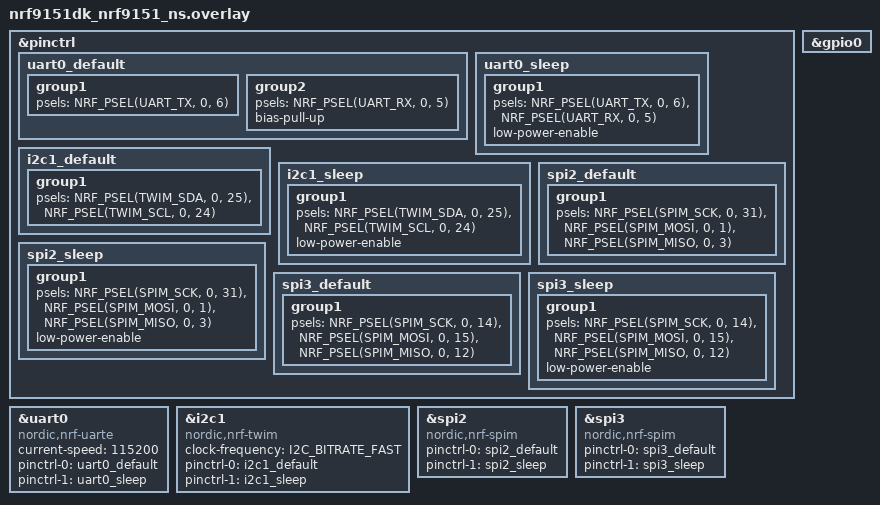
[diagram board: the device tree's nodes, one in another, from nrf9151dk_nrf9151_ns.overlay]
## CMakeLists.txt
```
#
# Copyright (c) 2023 Nordic Semiconductor
#
# SPDX-License-Identifier: LicenseRef-Nordic-5-Clause
#

cmake_minimum_required(VERSION 3.20.0)

find_package(Zephyr REQUIRED HINTS $ENV{ZEPHYR_BASE})
project(N2)
zephyr_compile_definitions(PROJECT_NAME=${PROJECT_NAME})

# NORDIC SDK APP START
target_sources(app PRIVATE src/main.c)
# NORDIC SDK APP END

# Include source directory
target_include_directories(app PRIVATE src)
target_include_directories(app PRIVATE $ENV{ZEPHYR_BASE}/subsys/fs/nvs)

# Application directories
add_subdirectory(src/menu)
add_subdirectory(src/datetime)
add_subdirectory(src/strings)
add_subdirectory(src/font)
add_subdirectory(src/image)
add_subdirectory(src/lcd)
add_subdirectory(src/key)
add_subdirectory(src/settings)
add_subdirectory(src/inner_flash)
add_subdirectory(src/external_flash)
add_subdirectory(src/uart)
add_subdirectory(src/gps)
add_subdirectory(src/nb)
add_subdirectory(src/screen)
add_subdirectory(src/pmu)
add_subdirectory(src/sos)
add_subdirectory(src/codetrans)
add_subdirectory(src/ucs2)
add_subdirectory(src/communicate)
add_subdirectory(src/logger)

add_subdirectory_ifdef(CONFIG_ALARM_SUPPORT src/alarm)
add_subdirectory_ifdef(CONFIG_ANIMATION_SUPPORT src/animation)
add_subdirectory_ifdef(CONFIG_TOUCH_SUPPORT src/tp)
add_subdirectory_ifdef(CONFIG_IMU_SUPPORT src/imu)
add_subdirectory_ifdef(CONFIG_PPG_SUPPORT src/ppg)
add_subdirectory_ifdef(CONFIG_ECG_SUPPORT src/ecg)
add_subdirectory_ifdef(CONFIG_BLE_SUPPORT src/ble)
add_subdirectory_ifdef(CONFIG_AUDIO_SUPPORT src/audio)
add_subdirectory_ifdef(CONFIG_TEMP_SUPPORT src/temperature)
add_subdirectory_ifdef(CONFIG_CRC_SUPPORT src/crc_check)
add_subdirectory_ifdef(CONFIG_SYNC_SUPPORT src/sync)
add_subdirectory_ifdef(CONFIG_WIFI_SUPPORT src/wifi)
add_subdirectory_ifdef(CONFIG_WATCHDOG src/watchdog)
add_subdirectory_ifdef(CONFIG_FOTA_DOWNLOAD src/fota)
add_subdirectory_ifdef(CONFIG_DATA_DOWNLOAD_SUPPORT src/data_download)
add_subdirectory_ifdef(CONFIG_BARCODE_SUPPORT src/barcode)
add_subdirectory_ifdef(CONFIG_QRCODE_SUPPORT src/qrcode)
add_subdirectory_ifdef(CONFIG_FACTORY_TEST_SUPPORT src/factory_test)
add_subdirectory_ifdef(CONFIG_PRESSURE_SUPPORT src/pressure)
```

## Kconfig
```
#
# Copyright (c) 2021 Nordic Semiconductor ASA
#
# SPDX-License-Identifier: LicenseRef-Nordic-5-Clause
#
choice LOG_MODE
	default LOG_MODE_IMMEDIATE
endchoice

menu "GPS"
config GPS_SUPPORT
	bool "gps support"
	default n
endmenu #GPS

menu "GNSS"
choice
	default GNSS_SAMPLE_MODE_CONTINUOUS
	prompt "Select GNSS operation mode"

config GNSS_SAMPLE_MODE_CONTINUOUS
	bool "Continuous tracking"

config GNSS_SAMPLE_MODE_PERIODIC
	bool "Periodic fixes"

config GNSS_SAMPLE_MODE_TTFF_TEST
	bool "Time-to-first-fix (TTFF) test mode"
	select GNSS_SAMPLE_NMEA_ONLY
endchoice

if GNSS_SAMPLE_MODE_PERIODIC
config GNSS_SAMPLE_PERIODIC_INTERVAL
	int "Fix interval for periodic fixes"
	range 10 65535
	default 120
	help
	  Fix interval (in seconds) for periodic fixes.
config GNSS_SAMPLE_PERIODIC_TIMEOUT
	int "Fix timeout for periodic fixes"
	range 0 65535
	default 120
	help
	  Fix timeout (in seconds) for periodic fixes.
	  If set to zero, GNSS is allowed to run indefinitely until a valid PVT estimate is produced.
endif # GNSS_SAMPLE_MODE_PERIODIC

if GNSS_SAMPLE_MODE_TTFF_TEST
config GNSS_SAMPLE_MODE_TTFF_TEST_COLD_START
	bool "Delete GNSS data before each start (cold start)"
	help
	  When enabled, deletes all stored data from GNSS to force a cold start every time GNSS is started.
config GNSS_SAMPLE_MODE_TTFF_TEST_INTERVAL
	int "Time to wait between TTFF tests in seconds"
	range 1 604800
	default 120
endif # GNSS_SAMPLE_MODE_TTFF_TEST

config GNSS_SAMPLE_NMEA_ONLY
	bool "Output only NMEA strings"
	help
	  Outputs only NMEA strings from the GNSS.

endmenu

choice
	default GNSS_SAMPLE_ASSISTANCE_NONE
	prompt "Select whether GNSS assistance is used or not"

config GNSS_SAMPLE_ASSISTANCE_NONE
	bool "Assistance not used"

config GNSS_SAMPLE_ASSISTANCE_NRF_CLOUD
	bool "Use nRF Cloud A-GNSS"
	select NRF_CLOUD_REST
	imply NRF_CLOUD_AGNSS
	select MODEM_JWT
	select MODEM_INFO
	select DATE_TIME

config GNSS_SAMPLE_ASSISTANCE_SUPL
	bool "Use SUPL assistance"
	select SUPL_CLIENT_LIB

config GNSS_SAMPLE_ASSISTANCE_MINIMAL
	bool "Use factory almanac, LTE network time and MCC based location"
	select GNSS_SAMPLE_LTE_ON_DEMAND
	select SETTINGS
	select FCB
	select FLASH
	select FLASH_MAP
endchoice

if !GNSS_SAMPLE_ASSISTANCE_NONE
config GNSS_SAMPLE_LTE_ON_DEMAND
	bool "LTE is activated only when needed to fetch A-GNSS data"
	depends on !NRF_CLOUD_PGPS
	help
	  Activates LTE only when it is needed to fetch A-GNSS data. This is not supported when
	  P-GPS is enabled.

endif # !GNSS_SAMPLE_ASSISTANCE_NONE

if GNSS_SAMPLE_ASSISTANCE_SUPL
config GNSS_SAMPLE_SUPL_HOSTNAME
	string "SUPL server hostname"
	help
	  SUPL server hostname.

config GNSS_SAMPLE_SUPL_PORT
	int "SUPL server port number"
	range 0 65535
	default 7276
	help
	  SUPL server port number.
endif # GNSS_SAMPLE_ASSISTANCE_SUPL

if GNSS_SAMPLE_MODE_CONTINUOUS
choice
	default GNSS_SAMPLE_POWER_SAVING_DISABLED
	prompt "Select GNSS power saving mode (duty-cycling)"

config GNSS_SAMPLE_POWER_SAVING_DISABLED
	bool "No power saving"

config GNSS_SAMPLE_POWER_SAVING_MODERATE
	bool "Power saving without significant performance degradation"

config GNSS_SAMPLE_POWER_SAVING_HIGH
	bool "Power saving with acceptable performance degradation"
endchoice
endif # GNSS_SAMPLE_MODE_CONTINUOUS

config GNSS_SAMPLE_LOW_ACCURACY
	bool "Allow low accuracy fixes"
	help
	  Allows fixes with lower accuracy.

if GNSS_SAMPLE_ASSISTANCE_MINIMAL && GNSS_SAMPLE_LOW_ACCURACY
config GNSS_SAMPLE_ASSISTANCE_REFERENCE_ALT
	int "Reference altitude for 3-sat first fix in meters"
	range -32767 32767
	default -32767
	help
	  Reference altitude for 3-sat first fix in meters above the reference ellipsoid surface.
	  The default value -32767 implies that reference altitude is not injected.
endif # GNSS_SAMPLE_ASSISTANCE_MINIMAL && GNSS_SAMPLE_LOW_ACCURACY

menu "MQTT simple sample"
config APPLICATION_WORKQUEUE_STACK_SIZE
	int "Application workqueue stack size"
	default 1024

config APPLICATION_WORKQUEUE_PRIORITY
	int "Application workqueue priority"
	default SYSTEM_WORKQUEUE_PRIORITY
	
config MQTT_LOG_PUB_TOPIC
	string "MQTT log publish topic"
	default "device/e2/pushlog"

config MQTT_PUB_TOPIC
	string "MQTT publish topic"
	default "device/e2/pushdata"

config MQTT_SUB_TOPIC
	string "MQTT subscribe topic"
	default "my/subscribe/topic"

config MQTT_CLIENT_ID
	string "MQTT Client ID"
	default "my-client-id"

config MQTT_USER_NAME
	string "MQTT user name"
	default "admin123"
	
config MQTT_PASSWORD
	string "MQTT password"
	default "admin123"

config MQTT_DOMESTIC_BROKER_HOSTNAME
	string "MQTT broker hostname"
	default "mqtt.eclipse.org"

config MQTT_DOMESTIC_BROKER_PORT
	int "MQTT broker port"
	default 1883
	
config MQTT_FOREIGN_BROKER_HOSTNAME
	string "MQTT broker hostname"
	default "mqtt.eclipse.org"

config MQTT_FOREIGN_BROKER_PORT
	int "MQTT broker port"
	default 1883

config MQTT_MESSAGE_BUFFER_SIZE
	int "MQTT message buffer size"
	default 128

config MQTT_PAYLOAD_BUFFER_SIZE
	int "MQTT payload buffer size"
	default 128

config SEC_TAG
	int "Security tag to use for the connection"
	default 16842753

config PEER_VERIFY
	int "Peer verify parameter for mqtt_client"
	default 1
	help
		Set to 0 for VERIFY_NONE, 1 for VERIFY_OPTIONAL, and 2 for VERIFY_REQUIRED.

config MODEM_AUTO_REQUEST_POWER_SAVING_FEATURES
	bool "Auto request power saving features"
	default y

config LTE_EDRX_ENABLE
	bool "Enable LTE enhanced Discontinuous Reception"

config LTE_RAI_ENABLE
	bool "Enable LTE Release Assistance Indication"
endmenu

menu "WATCH DOG"
config WATCHDOG_TIMEOUT_MSEC
	int "Watchdog timeout in milliseconds"
	default 10000
endmenu

menu "ANIMATION"
config ANIMATION_SUPPORT
	bool "animation support"
	default n
endmenu #ANIMATION

menu "ANIMATION"
config ANIMATION_SUPPORT
	bool "animation support"
	default n
endmenu #ANIMATION

menu "TOUCH"
config TOUCH_SUPPORT
	bool "touch support"
	default n
endmenu #TOUCH

menu "WIFI"
config WIFI_SUPPORT
	bool "wifi support"
	default n
endmenu #WIFI

menu "PPG"
config PPG_SUPPORT
	bool "ppg support"
	default n
endmenu #PPG

menu "ECG"
config ECG_SUPPORT
	bool "ecg support"
	default n
endmenu #ECG

menu "IMU"
config IMU_SUPPORT
	bool "imu support"
	default n
config STEP_SUPPORT
	bool "step support"
	default n		
config SLEEP_SUPPORT
	bool "sleep support"
	default n		
config FALL_DETECT_SUPPORT
	bool "fall detect support"
	default n		
endmenu #IMU

menu "AUDIO"
config AUDIO_SUPPORT
	bool "ppg support"
	default n
endmenu #AUDIO

menu "BLE"
config BLE_SUPPORT
	bool "ble support"
	default n
endmenu #BLE

menu "SYNC"
config SYNC_SUPPORT
	bool "sync support"
	default n
endmenu #SYNC

menu "TEMPERATURE"
config TEMP_SUPPORT
	bool "temperature support"
	default n
endmenu #TEMPERATURE

menu "PRESSURE"
config PRESSURE_SUPPORT
	bool "pressure support"
	default n
endmenu #PRESSURE

menu "CRC"
config CRC_SUPPORT
	bool "crc check support"
	default n
endmenu #CRC

menu "DATA_DOWNLOAD"
config DATA_DOWNLOAD_SUPPORT
	bool "data download support"
	default n

config DOWNLOAD_CLIENT_TLS
	bool "download client tls"
	default n

config USE_HTTPS
	bool
	prompt "Use HTTPS for download"
	
config DATA_DOWNLOAD_HOST_CN
	string "Download host name(cn)"	
config DATA_DOWNLOAD_HOST_HK
	string "Download host name(hk)"	
# IMG	
config IMG_DATA_UPDATE
	bool "img update support"
	default n
config IMG_DATA_DOWNLOAD_FILE
	string "The file to download"

# FONT
config FONT_DATA_UPDATE
	bool "font update support"
	default n
config FONT_DATA_DOWNLOAD_FILE
	string "The file to download"

# PPG
config PPG_DATA_UPDATE
	bool "ppg update support"
	default n
config PPG_DATA_DOWNLOAD_FILE
	string "The file to download"

# STR
config STR_DATA_UPDATE
	bool "str update support"
	default n
config STR_DATA_DOWNLOAD_FILE
	string "The file to download"
	

endmenu #DATA_DOWNLOAD 

menu "IMG_UPDATE"
config DL_TARGET_UI
	bool "img ui update support"
	default n
endmenu #IMG_UPDATE

menu "FOTA_MQTT"
config FOTA_DOWNLOAD
	bool "fota support"
	default n
	
config FOTA_DOWNLOAD_HOST_CN
	string "Download host name(cn)"

config FOTA_DOWNLOAD_HOST_HK
	string "Download host name(hk)"

config FOTA_DOWNLOAD_FILE
	string "The file to download"

config APPLICATION_VERSION
	int "Application version"
	default 1
endmenu #FOTA_MQTT

menu "BAT CODE"
config BARCODE_SUPPORT
	bool "bar code support"
	default n
endmenu #BAT CODE

menu "QR CODE"
config QRCODE_SUPPORT
	bool "qr code support"
	default n
endmenu #QR CODE

menu "WRIST CHECK"
config WRIST_CHECK_SUPPORT
	bool "wrist check support"
	default n
endmenu #WRIST CHECK

menu "FACTORY_TEST"
config FACTORY_TEST_SUPPORT
	bool "factory test support"
	default n
endmenu #FACTORY_TEST_SUPPORT

menu "FAST_KEY"
config FAST_KEY_SUPPORT
	bool "fast key support"
	default n
endmenu #FAST_KEY_SUPPORT

menu "ALARM_SUPPORT"
config ALARM_SUPPORT
	bool "alarm support"
	default n
endmenu #ALARM_SUPPORT

menu "Zephyr Kernel"
source "Kconfig.zephyr"
endmenu

module = APPLICATION_MODULE
module-str = Application module
source "subsys/logging/Kconfig.template.log_config"
```

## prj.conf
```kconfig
#
# Copyright (c) 2022 Nordic Semiconductor ASA
#
# SPDX-License-Identifier: LicenseRef-Nordic-5-Clause
#
# General config
CONFIG_NEWLIB_LIBC=y
CONFIG_NEWLIB_LIBC_FLOAT_PRINTF=y
CONFIG_ASSERT=y
CONFIG_REBOOT=y
CONFIG_GPIO=y
CONFIG_TRUSTED_EXECUTION_NONSECURE=y

# Log
CONFIG_LOG=y
CONFIG_LOG_MODE_IMMEDIATE=y
CONFIG_USE_SEGGER_RTT=y
CONFIG_LOG_BACKEND_RTT=y
CONFIG_LOG_BACKEND_UART=n
CONFIG_LOG_DEFAULT_LEVEL=4
CONFIG_LOG_MODE_OVERFLOW=y
CONFIG_LOG_BACKEND_RTT_MODE_DROP=y
CONFIG_LOG_BACKEND_FORMAT_TIMESTAMP=n

# PinCtrl
CONFIG_PINCTRL=y
CONFIG_PINCTRL_NRF=y

# watch dog
CONFIG_WATCHDOG=y
CONFIG_WATCHDOG_TIMEOUT_MSEC=10000

# Modem
CONFIG_MODEM_INFO=y
CONFIG_NRF_MODEM_LIB=y
#CONFIG_NRF_MODEM_LIB_TRACE=y
#CONFIG_NRF_MODEM_LIB_TRACE_BACKEND_RTT=y

# NVS
CONFIG_NVS=y
CONFIG_NVS_LOG_LEVEL_DBG=y

# Console
CONFIG_CONSOLE_SUBSYS=n
CONFIG_CONSOLE_HANDLER=n
CONFIG_CONSOLE_GETCHAR=n
CONFIG_CONSOLE=y
CONFIG_RTT_CONSOLE=y
CONFIG_UART_CONSOLE=n

# Network
CONFIG_NETWORKING=y
CONFIG_NET_SOCKETS=y
CONFIG_NET_NATIVE=n
CONFIG_NET_IPV4=y
CONFIG_NET_IPV6=y

# Socket
CONFIG_POSIX_MAX_FDS=8

# LTE link control
CONFIG_LTE_LINK_CONTROL=y
CONFIG_LTE_NETWORK_USE_FALLBACK=n
CONFIG_LTE_NETWORK_TIMEOUT=180
CONFIG_LTE_NETWORK_MODE_LTE_M_GPS=n
CONFIG_LTE_NETWORK_MODE_NBIOT_GPS=y

# PSM
CONFIG_MODEM_AUTO_REQUEST_POWER_SAVING_FEATURES=y
# Set Periodic-TAU timer to 70 mins and Active-Time to 10 seconds.
CONFIG_LTE_PSM_REQ_RPTAU="00000111"
CONFIG_LTE_PSM_REQ_RAT="00000101"

# MQTT
CONFIG_MQTT_LIB=y
CONFIG_MQTT_LIB_TLS=n
CONFIG_MQTT_KEEPALIVE=60
CONFIG_MQTT_PUB_TOPIC="device/n2/pushdata"
CONFIG_MQTT_LOG_PUB_TOPIC="device/n2/pushlog"
CONFIG_MQTT_SUB_TOPIC="device/n2/"
CONFIG_MQTT_CLIENT_ID="my-client-id"
CONFIG_MQTT_USER_NAME="admin123"
CONFIG_MQTT_PASSWORD="admin123"
CONFIG_MQTT_DOMESTIC_BROKER_HOSTNAME="47.107.51.89"
CONFIG_MQTT_DOMESTIC_BROKER_PORT=1883
CONFIG_MQTT_FOREIGN_BROKER_HOSTNAME="18.135.53.53"
CONFIG_MQTT_FOREIGN_BROKER_PORT=1883
CONFIG_MQTT_MESSAGE_BUFFER_SIZE=2176
CONFIG_MQTT_PAYLOAD_BUFFER_SIZE=2048

# Library for buttons and LEDs
CONFIG_DK_LIBRARY=y

# Heap and stacks
CONFIG_HEAP_MEM_POOL_SIZE=16384
CONFIG_MAIN_STACK_SIZE=8192
CONFIG_SYSTEM_WORKQUEUE_STACK_SIZE=2048
CONFIG_HW_STACK_PROTECTION=y

# SPI
CONFIG_SPI=y
CONFIG_SPI_LOG_LEVEL_OFF=y

# I2C
CONFIG_I2C=y

# UART
CONFIG_SERIAL=y
CONFIG_UART_INTERRUPT_DRIVEN=y
CONFIG_UART_USE_RUNTIME_CONFIGURE=y
CONFIG_UART_0_NRF_TX_BUFFER_SIZE=4096

# ANIMATION
CONFIG_ANIMATION_SUPPORT=y

# PPG
CONFIG_PPG_SUPPORT=y

# ECG
CONFIG_ECG_SUPPORT=y

# Temperature
CONFIG_TEMP_SUPPORT=y

# Pressure
CONFIG_PRESSURE_SUPPORT=y

# IMU
CONFIG_IMU_SUPPORT=y
CONFIG_STEP_SUPPORT=n
CONFIG_SLEEP_SUPPORT=n
CONFIG_FALL_DETECT_SUPPORT=y

# GPS
CONFIG_GPS_SUPPORT=y
# Enable to use nRF Cloud A-GNSS
CONFIG_GNSS_SAMPLE_ASSISTANCE_NRF_CLOUD=n

# WIFI
CONFIG_WIFI_SUPPORT=y

# TP
CONFIG_TOUCH_SUPPORT=y

# AUDIO
CONFIG_AUDIO_SUPPORT=y

# BLE
CONFIG_BLE_SUPPORT=y

# Data Sync
CONFIG_SYNC_SUPPORT=y

# CRC Check
CONFIG_CRC_SUPPORT=y

# DEVICE POWER MANAGEMENT
CONFIG_PM_DEVICE=y

# Download client
CONFIG_DOWNLOAD_CLIENT=y
CONFIG_DOWNLOAD_CLIENT_MAX_HOSTNAME_SIZE=192
CONFIG_DOWNLOAD_CLIENT_MAX_FILENAME_SIZE=64
CONFIG_DOWNLOAD_CLIENT_STACK_SIZE=4096

# DATA UPDATE
CONFIG_DATA_DOWNLOAD_SUPPORT=y
CONFIG_DATA_DOWNLOAD_HOST_HK="aug-fm-files-hk.oss-cn-hongkong.aliyuncs.com"
CONFIG_DATA_DOWNLOAD_HOST_CN="aug-fm-files-cn.oss-cn-shenzhen.aliyuncs.com"
# IMG
CONFIG_IMG_DATA_UPDATE=y
CONFIG_IMG_DATA_DOWNLOAD_FILE="n2_img.bin"
# FONT
CONFIG_FONT_DATA_UPDATE=y
CONFIG_FONT_DATA_DOWNLOAD_FILE="n2_font.bin"
# PPG
CONFIG_PPG_DATA_UPDATE=y
CONFIG_PPG_DATA_DOWNLOAD_FILE="n2_ppg.bin"
# STR
CONFIG_STR_DATA_UPDATE=y
CONFIG_STR_DATA_DOWNLOAD_FILE="n2_str.bin"

# fota download
CONFIG_FOTA_DOWNLOAD=y
CONFIG_FOTA_DOWNLOAD_PROGRESS_EVT=y
CONFIG_FOTA_DOWNLOAD_HOST_HK="aug-fm-files-hk.oss-cn-hongkong.aliyuncs.com"
CONFIG_FOTA_DOWNLOAD_HOST_CN="aug-fm-files-cn.oss-cn-shenzhen.aliyuncs.com"
CONFIG_FOTA_DOWNLOAD_FILE="n2_update.bin"
# Image manager
CONFIG_IMG_MANAGER=y

# FLASH
CONFIG_FLASH=y
CONFIG_FLASH_PAGE_LAYOUT=y
CONFIG_FLASH_MAP=y
CONFIG_STREAM_FLASH=y
CONFIG_MPU_ALLOW_FLASH_WRITE=y
CONFIG_IMG_ERASE_PROGRESSIVELY=y
# DFU Target
CONFIG_DFU_TARGET=y
# Modem key management
CONFIG_MODEM_KEY_MGMT=y
# Application Upgrade support
CONFIG_BOOTLOADER_MCUBOOT=y

# bar encode
CONFIG_BARCODE_SUPPORT=n

# QR encode
CONFIG_QRCODE_SUPPORT=y

# wrist off check
CONFIG_WRIST_CHECK_SUPPORT=n

# Facotry test
CONFIG_FACTORY_TEST_SUPPORT=y

# Fast Key
CONFIG_FAST_KEY_SUPPORT=y

# Alarm
CONFIG_ALARM_SUPPORT=n

CONFIG_ENTROPY_GENERATOR=y
CONFIG_TEST_RANDOM_GENERATOR=y
```

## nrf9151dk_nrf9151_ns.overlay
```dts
/* SPDX-License-Identifier: Apache-2.0 */

&pinctrl
{
	uart0_default: uart0_default
	{
		group1
		{
			psels = <NRF_PSEL(UART_TX, 0, 6)>;
		};
		group2
		{
			psels = <NRF_PSEL(UART_RX, 0, 5)>;
			bias-pull-up;
		};
	};
	uart0_sleep: uart0_sleep
	{
		group1
		{
			psels = <NRF_PSEL(UART_TX, 0, 6)>,
							<NRF_PSEL(UART_RX, 0, 5)>;
			low-power-enable;
		};
	};
 
 	i2c1_default: i2c1_default
	{
		group1
		{
			psels = <NRF_PSEL(TWIM_SDA, 0, 25)>,
							<NRF_PSEL(TWIM_SCL, 0, 24)>;
		};
	};
	i2c1_sleep: i2c1_sleep
	{
		group1
		{
			psels = <NRF_PSEL(TWIM_SDA, 0, 25)>,
							<NRF_PSEL(TWIM_SCL, 0, 24)>;
			low-power-enable;
		};
	};
	
	spi2_default: spi2_default
	{
		group1
		{
			psels = <NRF_PSEL(SPIM_SCK,  0, 31)>,
							<NRF_PSEL(SPIM_MOSI, 0, 1)>,
							<NRF_PSEL(SPIM_MISO, 0, 3)>;
		};
	};
	spi2_sleep: spi2_sleep
	{
		group1
		{
			psels = <NRF_PSEL(SPIM_SCK,  0, 31)>,
							<NRF_PSEL(SPIM_MOSI, 0, 1)>,
							<NRF_PSEL(SPIM_MISO, 0, 3)>;
			low-power-enable;
		};
	};
	
	spi3_default: spi3_default
	{
		group1
		{
			psels = <NRF_PSEL(SPIM_SCK,  0, 14)>,
							<NRF_PSEL(SPIM_MOSI, 0, 15)>,
							<NRF_PSEL(SPIM_MISO, 0, 12)>;
		};
	};
	spi3_sleep: spi3_sleep
	{
		group1
		{
			psels = <NRF_PSEL(SPIM_SCK,  0, 14)>,
							<NRF_PSEL(SPIM_MOSI, 0, 15)>,
							<NRF_PSEL(SPIM_MISO, 0, 12)>;
			low-power-enable;
		};
	};
};

&gpio0{
	/delete-property/ gpio-reserved-ranges;
};

&uart0{
	compatible = "nordic,nrf-uarte";
	status = "okay";
	current-speed = <115200>;
	pinctrl-0 = <&uart0_default>;
	pinctrl-1 = <&uart0_sleep>;
	pinctrl-names = "default", "sleep";
	/delete-property/ rts-pin;
	/delete-property/ cts-pin;
};

/delete-node/ &uart1;

&i2c1{
	compatible = "nordic,nrf-twim";
	status = "okay";
	clock-frequency = <I2C_BITRATE_FAST>;
	pinctrl-0 = <&i2c1_default>;
	pinctrl-1 = <&i2c1_sleep>;
	pinctrl-names = "default", "sleep";
};

/delete-node/ &i2c2;

&spi2{	
	compatible = "nordic,nrf-spim";
	status = "okay";
	pinctrl-0 = <&spi2_default>;
	pinctrl-1 = <&spi2_sleep>;
	pinctrl-names = "default", "sleep";
};

&spi3{
	compatible = "nordic,nrf-spim";
	status = "okay";
	pinctrl-0 = <&spi3_default>;
	pinctrl-1 = <&spi3_sleep>;
	pinctrl-names = "default", "sleep";
};
```

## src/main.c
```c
/*
* Copyright (c) 2019 Nordic Semiconductor ASA
*
* SPDX-License-Identifier: LicenseRef-BSD-5-Clause-Nordic
*/

#include <zephyr/kernel.h>
#include <zephyr/device.h>
#include <stdio.h>
#include <zephyr/sys/printk.h>
#include <zephyr/sys/reboot.h>
#include <zephyr/dfu/mcuboot.h>
#include <zephyr/drivers/spi.h>
#include <zephyr/drivers/gpio.h>
#include <modem/nrf_modem_lib.h>
#include <dk_buttons_and_leds.h>
#include "lcd.h"
#include "datetime.h"
#include "font.h"
#include "img.h"
#include "inner_flash.h"
#include "external_flash.h"
#include "uart.h"
#include "settings.h"
#include "screen.h"
#ifdef CONFIG_DATA_DOWNLOAD_SUPPORT
#include "data_download.h"
#endif/*CONFIG_DATA_DOWNLOAD_SUPPORT*/
#ifdef CONFIG_TOUCH_SUPPORT
#include "CST816.h"
#endif
#include "Max20353.h"
#ifdef CONFIG_IMU_SUPPORT
#include "lsm6dso.h"
#endif
#ifdef CONFIG_GPS_SUPPORT
#include "gps.h"
#endif
#include "pmu.h"
#include "screen.h"
#include "codetrans.h"
#ifdef CONFIG_AUDIO_SUPPORT
#include "audio.h"
#endif
#ifdef CONFIG_WATCHDOG
#include "watchdog.h"
#endif
#ifdef CONFIG_PRESSURE_SUPPORT
#include "pressure.h"
#endif
#ifdef CONFIG_WIFI_SUPPORT
#include "esp8266.h"
#endif/*CONFIG_WIFI_SUPPORT*/
#include "logger.h"

static bool sys_pwron_completed_flag = false;

/* Stack definition for application workqueue */
K_THREAD_STACK_DEFINE(nb_stack_area,
		      4096);
static struct k_work_q nb_work_q;

#ifdef CONFIG_IMU_SUPPORT
K_THREAD_STACK_DEFINE(imu_stack_area,
              2048);
static struct k_work_q imu_work_q;
#endif

K_THREAD_STACK_DEFINE(gps_stack_area,
              4096);
static struct k_work_q gps_work_q;



void test_show_image(void)
{
	uint8_t i=0,strbuf[64]={0};
	uint16_t x,y,w=0,h=0;
	
	LCD_Clear(BLACK);

	LCD_ShowImage(IDLE_SIGNAL_X, IDLE_SIGNAL_Y, IMG_ID_SIG_4);
	
	LCD_ShowImage(IDLE_NET_MODE_X, IDLE_NET_MODE_Y, IMG_ID_NET_NB);

	sprintf(strbuf, "%d%%", 100);
	LCD_SetFontSize(FONT_SIZE_28);
	LCD_MeasureString(strbuf, &w, &h);
	LCD_ShowString((IDLE_BAT_X-w)-4, IDLE_BAT_PERCENT_Y, strbuf);
	
	LCD_ShowImage(IDLE_BAT_X, IDLE_BAT_Y, IMG_ID_BAT_RECT_WHITE);
	//LCD_Fill(IDLE_BAT_INNER_RECT_X, IDLE_BAT_INNER_RECT_Y, (100*IDLE_BAT_INNER_RECT_W)/100, IDLE_BAT_INNER_RECT_H, GREEN);
	//LCD_get_pic_size(peppa_pig_160X160, &w, &h);
	//LCD_dis_pic_rotate(0,200,peppa_pig_160X160,270);
	//LCD_dis_pic(0, 0, peppa_pig_160X160);
	//LCD_MeasureImage(IMG_ID_TEMP_MIN_REC, &w, &h);
	//LCD_ShowImage((LCD_WIDTH-w)/2, (LCD_HEIGHT-h)/2, IMG_ID_TEMP_MIN_REC);
	//LCD_dis_pic_rotate_from_flash((LCD_WIDTH-w)/2, (LCD_HEIGHT-h)/2, IMG_ANALOG_CLOCK_HAND_HOUR_ADDR, 270);
	//LCD_dis_pic_angle_from_flash(0, 0, IMG_ANALOG_CLOCK_HAND_SEC_ADDR, 360);
	while(0)
	{
	#if 0	
		switch(i)
		{
			case 0:
				//LCD_dis_pic(w*0,h*0,peppa_pig_160X160);
				//LCD_dis_pic_trans(w*0,h*0,peppa_pig_80X160,WHITE);
				LCD_dis_pic_from_flash(w*0, h*0, IMG_ANALOG_CLOCK_BG_ADDR);
				//LCD_dis_pic_rotate((LCD_WIDTH-w)/2,(LCD_HEIGHT-h)/2,peppa_pig_160X160,0);
				//LCD_dis_pic_trans_rotate((LCD_WIDTH-w)/2,(LCD_HEIGHT-h)/2,peppa_pig_160X160,WHITE,0);
				break;
			case 1:
				//LCD_dis_pic(w*1,h*0,peppa_pig_160X160);
				//LCD_dis_pic_trans(w*1,h*0,peppa_pig_80X160,WHITE);
				LCD_dis_pic_from_flash(w*1, h*0, IMG_ANALOG_CLOCK_BG_ADDR);
				//LCD_dis_pic_rotate((LCD_WIDTH-w)/2,(LCD_HEIGHT-h)/2,peppa_pig_160X160,90);
				//LCD_dis_pic_trans_rotate((LCD_WIDTH-w)/2,(LCD_HEIGHT-h)/2,peppa_pig_160X160,WHITE,90);
				break;
			case 2:
				//LCD_dis_pic(w*1,h*1,peppa_pig_160X160);
				//LCD_dis_pic_trans(w*1,h*1,peppa_pig_80X160,WHITE);
				LCD_dis_pic_from_flash(w*1, h*1, IMG_ANALOG_CLOCK_BG_ADDR);
				//LCD_dis_pic_rotate((LCD_WIDTH-w)/2,(LCD_HEIGHT-h)/2,peppa_pig_160X160,180);
				//LCD_dis_pic_trans_rotate((LCD_WIDTH-w)/2,(LCD_HEIGHT-h)/2,peppa_pig_160X160,WHITE,180);
				break;
			case 3:
				//LCD_dis_pic(w*0,h*1,peppa_pig_160X160);
				//LCD_dis_pic_trans(w*0,h*1,peppa_pig_80X160,WHITE);
				LCD_dis_pic_from_flash(w*0, h*1, IMG_ANALOG_CLOCK_BG_ADDR);
				//LCD_dis_pic_rotate((LCD_WIDTH-w)/2,(LCD_HEIGHT-h)/2,peppa_pig_160X160,270);
				//LCD_dis_pic_trans_rotate((LCD_WIDTH-w)/2,(LCD_HEIGHT-h)/2,peppa_pig_160X160,WHITE,270);
				break;
			case 4:
				LCD_Fill(w*0,h*0,w,h,BLACK);
				break;
			case 5:
				LCD_Fill(w*1,h*0,w,h,BLACK);
				break;
			case 6:
				LCD_Fill(w*1,h*1,w,h,BLACK);
				break;
			case 7:
				LCD_Fill(w*0,h*1,w,h,BLACK);
				break;
		}
	#endif

		i++;
		if(i==23)
			i = 0;
		
		k_sleep(K_MSEC(1000));								//ï¿½ï¿½ï¿½ï¿½ï¿½ï¿½Ê±1000ms
	}
}

void test_show_stripe(void)
{
	uint16_t x,y,w,h;
	uint8_t i;
	uint16_t color[] = {WHITE,BLACK,RED,GREEN,BLUE,GBLUE,MAGENTA,CYAN,YELLOW,BROWN,BRRED,GRAY};
	
	h = LCD_HEIGHT/8;

	for(i=0;i<8;i++)
	{
		LCD_Fill(0, h*i, LCD_WIDTH, h, color[i%5]);
	}
}

void test_show_color(void)
{
	uint8_t i=0;

	LOGD("test_show_color");
	
	while(1)
	{
		switch(i)
		{
			case 0:
				LCD_Clear(WHITE);
				break;
			case 1:
				LCD_Clear(BLACK);
				break;
			case 2:
				LCD_Clear(RED);
				break;
			case 3:
				LCD_Clear(GREEN);
				break;
			case 4:
				LCD_Clear(BLUE);
				break;
			case 5:
				LCD_Clear(YELLOW);
				break;
			case 6:
				LCD_Clear(GBLUE);
				break;
			case 7:
				LCD_Clear(MAGENTA);
				break;
			case 8:
				LCD_Clear(CYAN);
				break;
			case 9:
				LCD_Clear(BROWN);
				break;
			case 10:
				LCD_Clear(BRRED);
				break;
			case 11:
				LCD_Clear(GRAY);
				break;					
		}
		
		i++;
		if(i>=12)
			i=0;
		
		k_sleep(K_MSEC(1000));								//ï¿½ï¿½ï¿½ï¿½ï¿½ï¿½Ê±1000ms
	}
}

void test_show_string(void)
{
	uint16_t x,y,w,h;
	uint8_t tmpbuf[256] = {0};
	uint16_t test_buf[] = {0x6DF1,0x5733,0x5E02,0x0041,0x0075,0x0067,0x0075,0x0073,0x0074,0x6570,0x7801,0x0030,0x0031,0x0032,0x0033,0x0034,0x0035,0x0000};//ÉîÛÚÊÐAugustÊýÂë012345

	LCD_Clear(BLACK);
	
	POINT_COLOR=WHITE;								//ï¿½ï¿½ï¿½ï¿½ï¿½ï¿½É«
	BACK_COLOR=BLACK;  								//ï¿½ï¿½ï¿½ï¿½É« 

#ifdef FONTMAKER_UNICODE_FONT
#if 0//def FONT_68
	LCD_SetFontSize(FONT_SIZE_68);					//ï¿½ï¿½ï¿½ï¿½ï¿½ï¿½ï¿½ï¿½ï¿½Ð¡
#elif 0//defined(FONT_48)
	LCD_SetFontSize(FONT_SIZE_48);					//ï¿½ï¿½ï¿½ï¿½ï¿½ï¿½ï¿½ï¿½ï¿½Ð¡
#elif 0//defined(FONT_32)
	LCD_SetFontSize(FONT_SIZE_32);					//ï¿½ï¿½ï¿½ï¿½ï¿½ï¿½ï¿½ï¿½ï¿½Ð¡	
#elif defined(FONT_28)
	//LCD_SetFontSize(FONT_SIZE_28);					//ï¿½ï¿½ï¿½ï¿½ï¿½ï¿½ï¿½ï¿½ï¿½Ð¡	
#elif defined(FONT_20)
	//LCD_SetFontSize(FONT_SIZE_20);		
#elif defined(FONT_24)
	//LCD_SetFontSize(FONT_SIZE_24);					//ï¿½ï¿½ï¿½ï¿½ï¿½ï¿½ï¿½ï¿½ï¿½Ð¡
#elif defined(FONT_16)
	//LCD_SetFontSize(FONT_SIZE_16);					//ï¿½ï¿½ï¿½ï¿½ï¿½ï¿½ï¿½ï¿½ï¿½Ð¡
#endif
	//LCD_MeasureUniString(test_buf, &w, &h);

	LCD_SetFontSize(FONT_SIZE_20);
	LCD_MeasureUniString(test_buf, &w, &h);
	LCD_ShowUniString((LCD_WIDTH-w)/2,200,test_buf);
	LCD_SetFontSize(FONT_SIZE_28);
	LCD_MeasureUniString(test_buf, &w, &h);
	LCD_ShowUniString((LCD_WIDTH-w)/2,240,test_buf);
	//LCD_SetFontSize(FONT_SIZE_36);
	//LCD_MeasureUniString(test_buf, &w, &h);
	//LCD_ShowUniString(20,130,test_buf);

#else

	strcpy(enbuf, "August Shenzhen Digital Ltd");
	strcpy(cnbuf, "ï¿½ï¿½ï¿½ï¿½ï¿½Ð°Â¿ï¿½Ë¹ï¿½ï¿½ï¿½ï¿½ï¿½ï¿½ï¿½Þ¹ï¿½Ë¾");
	strcpy(jpbuf, "ï¿½î¥»ï¿½ï¿½ï¿½Ð¥ï¿½ï¿½`ï¿½ï¿½ï¿½ï¿½ï¿½Ç¥ï¿½ï¿½ï¿½ï¿½ï¿½ï¿½ï¿½ï¿½Þ»ï¿½ï¿½ï¿½");

#ifdef FONT_32
	LCD_SetFontSize(FONT_SIZE_32);					//ï¿½ï¿½ï¿½ï¿½ï¿½ï¿½ï¿½ï¿½ï¿½Ð¡	
#elif defined(FONT_24)
	LCD_SetFontSize(FONT_SIZE_24);					//ï¿½ï¿½ï¿½ï¿½ï¿½ï¿½ï¿½ï¿½ï¿½Ð¡
#elif defined(FONT_16)
	LCD_SetFontSize(FONT_SIZE_16);					//ï¿½ï¿½ï¿½ï¿½ï¿½ï¿½ï¿½ï¿½ï¿½Ð¡
#endif

	LCD_MeasureString(enbuf,&w,&h);
	x = (w > LCD_WIDTH)? 0 : (LCD_WIDTH-w)/2;
	y = y + h + 2;	
	LCD_ShowString(x,y,enbuf);
	
	LCD_MeasureString(cnbuf,&w,&h);
	x = (w > LCD_WIDTH)? 0 : (LCD_WIDTH-w)/2;
	y = y + h + 2;
	LCD_ShowString(x,y,cnbuf);
	
	LCD_MeasureString(jpbuf,&w,&h);
	x = (w > LCD_WIDTH)? 0 : (LCD_WIDTH-w)/2;
	y = y + h + 2;
	LCD_ShowString(x,y,jpbuf);

#endif
}

void test_show_lines(void)
{
	uint8_t i;

	for(i=0;i<8;i++)
	{
		LCD_DrawLine(0, 20+60*i, LCD_WIDTH-1, 20+60*i);
	}

	for(i=0;i<8;i++)
	{
		LCD_DrawLine(20+60*i, 0, 20+60*i, LCD_HEIGHT-1);
	}
}

void test_notify(void)
{
	notify_infor infor = {0};
	uint16_t str_note[LANGUAGE_MAX][80] = {
											{0x0054,0x0068,0x0065,0x0020,0x0074,0x0069,0x006D,0x0069,0x006E,0x0067,0x0020,0x006D,0x0065,0x0061,0x0073,0x0075,0x0072,0x0065,0x006D,0x0065,0x006E,0x0074,0x0020,0x0069,0x0073,0x0020,0x0061,0x0062,0x006F,0x0075,0x0074,0x0020,0x0074,0x006F,0x0020,0x0073,0x0074,0x0061,0x0072,0x0074,0x002C,0x0020,0x0061,0x006E,0x0064,0x0020,0x0074,0x0068,0x0069,0x0073,0x0020,0x006D,0x0065,0x0061,0x0073,0x0075,0x0072,0x0065,0x006D,0x0065,0x006E,0x0074,0x0020,0x0069,0x0073,0x0020,0x006F,0x0076,0x0065,0x0072,0x0021,0x0000},//The timing measurement is about to start, and this measurement is over!
											{0x0044,0x0069,0x0065,0x0020,0x005A,0x0065,0x0069,0x0074,0x006D,0x0065,0x0073,0x0073,0x0075,0x006E,0x0067,0x0020,0x0073,0x0074,0x0065,0x0068,0x0074,0x0020,0x006B,0x0075,0x0072,0x007A,0x0020,0x0062,0x0065,0x0076,0x006F,0x0072,0x002C,0x0020,0x0075,0x006E,0x0064,0x0020,0x0064,0x0069,0x0065,0x0073,0x0065,0x0020,0x004D,0x0065,0x0073,0x0073,0x0075,0x006E,0x0067,0x0020,0x0069,0x0073,0x0074,0x0020,0x0076,0x006F,0x0072,0x0062,0x0065,0x0069,0x0021,0x0000},//Die Zeitmessung steht kurz bevor, und diese Messung ist vorbei!
											{0x5B9A,0x65F6,0x6D4B,0x91CF,0x5373,0x5C06,0x5F00,0x59CB,0xFF0C,0x672C,0x6B21,0x6D4B,0x91CF,0x7ED3,0x675F,0xFF01,0x0000},//ï¿½ï¿½Ê±ï¿½ï¿½ï¿½ï¿½ï¿½ï¿½ï¿½ï¿½ï¿½ï¿½Ê¼ï¿½ï¿½ï¿½ï¿½ï¿½Î²ï¿½ï¿½ï¿½ï¿½ï¿½ï¿½ï¿½ï¿½ï¿½
										};

	LCD_SetFontSize(FONT_SIZE_20);
	
	infor.x = 0;
	infor.y = 0;
	infor.w = LCD_WIDTH;
	infor.h = LCD_HEIGHT;

	infor.align = NOTIFY_ALIGN_CENTER;
	infor.type = NOTIFY_TYPE_POPUP;

	infor.img_count = 0;
	mmi_ucs2cpy(infor.text, (uint8_t*)str_note[0]);

	DisplayPopUp(infor);
}

static void modem_init(void)
{
	int ret,type;
	
	ret = nrf_modem_lib_init();
	if(ret)
	{
		LOGD("ret: %d", ret);
		if(ret != -EAGAIN && ret != -EIO)
		{
			return ret;
		}
		else if(ret == -EIO)
		{
			LOGD("Please program full modem firmware with the bootloader or external tools");
		}
	}

	type = mcuboot_swap_type();
	switch(type)
	{
	/** Attempt to boot the contents of slot 0. */
	case BOOT_SWAP_TYPE_NONE:
		/* Normal reset, nothing happened, do nothing. */
		LOGD("BOOT_SWAP_TYPE_NONE");
		return;

	/** Swap to slot 1. Absent a confirm command, revert back on next boot. */
	case BOOT_SWAP_TYPE_TEST:
		LOGD("BOOT_SWAP_TYPE_TEST");
		break;

	/** Swap to slot 1, and permanently switch to booting its contents. */
	case BOOT_SWAP_TYPE_PERM:
		LOGD("BOOT_SWAP_TYPE_PERM");
		break;
		
	/** Swap failed because image to be run is not valid. */
	case BOOT_SWAP_TYPE_FAIL:
		LOGD("BOOT_SWAP_TYPE_FAIL");
		break;

	/** Swap back to alternate slot. A confirm changes this state to NONE. */
	case BOOT_SWAP_TYPE_REVERT:
		/* Happens on a successful application FOTA. */
		LOGD("BOOT_SWAP_TYPE_REVERT");
		ret = boot_write_img_confirmed();
		LOGD("ret:%d", ret);
		break;
	}
}

void system_init(void)
{
	uart_init();
	pmu_init();

	modem_init();
#ifdef CONFIG_FOTA_DOWNLOAD
	fota_init();
#endif

	InitSystemSettings();

#ifdef CONFIG_IMU_SUPPORT
	init_imu_int1();//xb add 2022-05-27
#endif
	key_init();
#ifdef CONFIG_TOUCH_SUPPORT
	tp_init();
#endif
	LCD_Init();
	flash_init();
	
	ShowBootUpLogo();
	
#ifdef CONFIG_AUDIO_SUPPORT	
	audio_init();
#endif
#ifdef CONFIG_BLE_SUPPORT
	BLE_init();
#endif
#ifdef CONFIG_ECG_SUPPORT
	ECG_init();
#endif
#ifdef CONFIG_IMU_SUPPORT
	IMU_init(&imu_work_q);
#endif
#ifdef CONFIG_PPG_SUPPORT
	PPG_init();
#endif
#ifdef CONFIG_PRESSURE_SUPPORT
	pressure_init();
#endif
#ifdef CONFIG_TEMP_SUPPORT
	temp_init();
#endif
#ifdef CONFIG_WIFI_SUPPORT
	wifi_init();
#endif
#ifdef CONFIG_DATA_DOWNLOAD_SUPPORT
	dl_init();
#endif
	LogInit();

	NB_init(&nb_work_q);
	GPS_init(&gps_work_q);
}

void work_init(void)
{
	k_work_queue_start(&nb_work_q, nb_stack_area,
					K_THREAD_STACK_SIZEOF(nb_stack_area),
					CONFIG_APPLICATION_WORKQUEUE_PRIORITY,NULL);
#ifdef CONFIG_IMU_SUPPORT	
	k_work_queue_start(&imu_work_q, imu_stack_area,
					K_THREAD_STACK_SIZEOF(imu_stack_area),
					K_HIGHEST_APPLICATION_THREAD_PRIO,NULL);
#endif
	k_work_queue_start(&gps_work_q, gps_stack_area,
					K_THREAD_STACK_SIZEOF(gps_stack_area),
					CONFIG_APPLICATION_WORKQUEUE_PRIORITY,NULL);	
	
	if(IS_ENABLED(CONFIG_WATCHDOG))
	{
		watchdog_init_and_start(&k_sys_work_q);
	}
}

bool system_is_completed(void)
{
	return sys_pwron_completed_flag;
}

void system_init_completed(void)
{
	if(!sys_pwron_completed_flag)
		sys_pwron_completed_flag = true;
}

/***************************************************************************
* ï¿½ï¿½  ï¿½ï¿½ : mainï¿½ï¿½ï¿½ï¿½ 
* ï¿½ï¿½  ï¿½ï¿½ : ï¿½ï¿½ 
* ï¿½ï¿½ï¿½ï¿½Öµ : int ï¿½ï¿½ï¿½ï¿½
**************************************************************************/
int main(void)
{
	LOGD("begin");

	work_init();
	system_init();
	
//	test_show_string();
//	test_show_image();
//	test_show_color();
//	test_show_stripe();
//	test_show_lines();
//	test_nvs();
//	test_flash();
//	test_uart_ble();
//	test_sensor();
//	test_show_digital_clock();
//	test_sensor();
//	test_pmu();
//	test_crypto();
//	test_imei_for_qr();
//	test_tp();
//	test_gps_on();
//	test_nb();
//	test_i2c();
//	test_bat_soc();
//	test_notify();
//	test_wifi();
//	LogInit();

	while(1)
	{
		KeyMsgProcess();
	#ifdef CONFIG_TOUCH_SUPPORT
		TPMsgProcess();
	#endif
		TimeMsgProcess();
		NBMsgProcess();
		GPSMsgProcess();
		PMUMsgProcess();
		LCDMsgProcess();
		SettingsMsgPorcess();
		SOSMsgProc();
		UartMsgProc();
	#ifdef CONFIG_ALARM_SUPPORT
		AlarmMsgProcess();
	#endif
	#ifdef CONFIG_AUDIO_SUPPORT	
		AudioMsgProcess();
	#endif
	#ifdef CONFIG_BLE_SUPPORT
		BLEMsgProcess();
	#endif
	#ifdef CONFIG_IMU_SUPPORT	
		IMUMsgProcess();
	#ifdef CONFIG_FALL_DETECT_SUPPORT
		FallMsgProcess();
	#endif
	#endif
	#ifdef CONFIG_PPG_SUPPORT	
		PPGMsgProcess();
	#endif
	#ifdef CONFIG_ECG_SUPPORT
		ECGMsgProcess();
	#endif
	#ifdef CONFIG_PRESSURE_SUPPORT
		PressureMsgProcess();
	#endif
	#ifdef CONFIG_TEMP_SUPPORT
		TempMsgProcess();
	#endif
	#ifdef CONFIG_TOUCH_SUPPORT
		TPMsgProcess();
	#endif
	#ifdef CONFIG_ALARM_SUPPORT
		AlarmMsgProcess();
	#endif
	#ifdef CONFIG_WIFI_SUPPORT
		WifiMsgProcess();
	#endif	
	#ifdef CONFIG_ANIMATION_SUPPORT
		AnimaMsgProcess();
	#endif		
	#ifdef CONFIG_DATA_DOWNLOAD_SUPPORT
		DlMsgProc();
	#endif
	#ifdef CONFIG_FOTA_DOWNLOAD
		VerCheckMsgProc();
		FotaMsgProc();
	#endif
	#ifdef CONFIG_AUDIO_SUPPORT
		AudioMsgProcess();
	#endif
	#ifdef CONFIG_SYNC_SUPPORT
		SyncMsgProcess();
	#endif
	#ifdef CONFIG_TEMP_SUPPORT
		TempMsgProcess();
	#endif
	#ifdef CONFIG_PRESSURE_SUPPORT
		PressureMsgProcess();
	#endif
	#ifdef CONFIG_FACTORY_TEST_SUPPORT
		FactoryTestProccess();
	#endif
	#ifdef CONFIG_LOG
		LogMsgProcess();
	#endif
		ScreenMsgProcess();
		system_init_completed();
		k_cpu_idle();
	}
}
```
